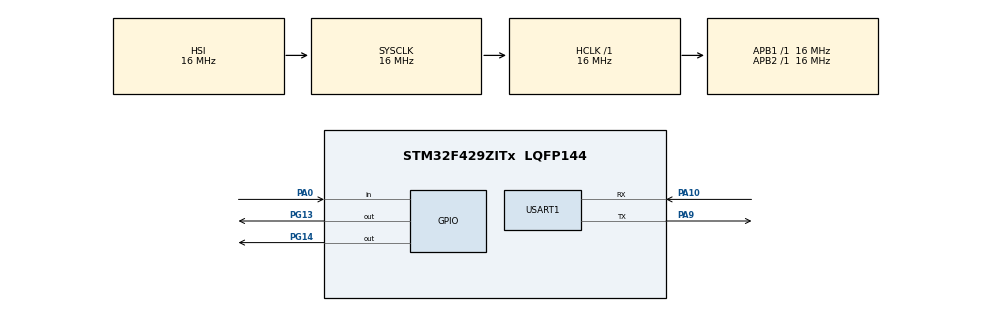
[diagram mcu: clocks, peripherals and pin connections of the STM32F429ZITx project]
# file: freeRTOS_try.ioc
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FREERTOS.BinarySemaphores01=myBinarySem01,Dynamic,NULL
FREERTOS.Tasks01=defaultTask,0,128,Thread1,Default,NULL,Dynamic,NULL,NULL;myTask02,-2,128,Thread2,Default,NULL,Dynamic,NULL,NULL
Mcu.Family=STM32F4
Mcu.Name=STM32F429ZITx
Mcu.Package=LQFP144
NVIC.PriorityGroup=NVIC_PRIORITYGROUP_4
NVIC.TIM3_IRQn=true\:0\:0\:false\:false\:true\:false\:false\:true
NVIC.TimeBase=TIM3_IRQn
NVIC.TimeBaseIP=TIM3
PA0/WKUP.Signal=GPIO_Input
PA10.Mode=Asynchronous
PA10.Signal=USART1_RX
PA13.Mode=Serial_Wire
PA13.Signal=SYS_JTMS-SWDIO
PA14.Mode=Serial_Wire
PA14.Signal=SYS_JTCK-SWCLK
PA9.Mode=Asynchronous
PA9.Signal=USART1_TX
PG13.Signal=GPIO_Output
PG14.Signal=GPIO_Output
ProjectManager.HeapSize=0x200
ProjectManager.StackSize=0x400
ProjectManager.TargetToolchain=MDK-ARM V5
RCC.AHBFreq_Value=16000000
RCC.APB1Freq_Value=16000000
RCC.APB2Freq_Value=16000000
RCC.CortexFreq_Value=16000000
RCC.HSE_VALUE=25000000
RCC.HSI_VALUE=16000000
RCC.LSE_VALUE=32768
RCC.SYSCLKFreq_VALUE=16000000
RCC.VCOOutputFreq_Value=192000000
USART1.VirtualMode=VM_ASYNC
VP_FREERTOS_VS_CMSIS_V1.Mode=CMSIS_V1
VP_SYS_VS_tim3.Mode=TIM3
board=custom

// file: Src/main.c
/* USER CODE BEGIN Header */
/**
  ******************************************************************************
  * @file           : main.c
  * @brief          : Main program body
  ******************************************************************************
  * @attention
  *
  * <h2><center>&copy; Copyright (c) 2020 STMicroelectronics.
  * All rights reserved.</center></h2>
  *
  * This software component is licensed by ST under Ultimate Liberty license
  * SLA0044, the "License"; You may not use this file except in compliance with
  * the License. You may obtain a copy of the License at:
  *                             www.st.com/SLA0044
  *
  ******************************************************************************
  */
/* USER CODE END Header */

#include "main.h"
#include "cmsis_os.h"

UART_HandleTypeDef huart1;

osThreadId defaultTaskHandle;
osThreadId myTask02Handle;
osSemaphoreId myBinarySem01Handle;

void SystemClock_Config(void);
static void MX_GPIO_Init(void);
static void MX_USART1_UART_Init(void);
void Thread1(void const * argument);
void Thread2(void const * argument);

int main(void)
{

  /* MCU Configuration--------------------------------------------------------*/

  /* Reset of all peripherals, Initializes the Flash interface and the Systick. */
  HAL_Init();

  /* Configure the system clock */
  SystemClock_Config();

  /* Initialize all configured peripherals */
  MX_GPIO_Init();
  MX_USART1_UART_Init();

  /* Create the semaphores(s) */
  /* definition and creation of myBinarySem01 */
  osSemaphoreDef(myBinarySem01);
  myBinarySem01Handle = osSemaphoreCreate(osSemaphore(myBinarySem01), 1);

  /* Create the thread(s) */
  /* definition and creation of defaultTask */
  osThreadDef(defaultTask, Thread1, osPriorityNormal, 0, 128);
  defaultTaskHandle = osThreadCreate(osThread(defaultTask), NULL);

  /* definition and creation of myTask02 */
  osThreadDef(myTask02, Thread2, osPriorityLow, 0, 128);
  myTask02Handle = osThreadCreate(osThread(myTask02), NULL);

  /* Start scheduler */
  osKernelStart();

  /* We should never get here as control is now taken by the scheduler */

  /* Infinite loop */
  while (1)
  {

  }
}

void SystemClock_Config(void)
{
  RCC_OscInitTypeDef RCC_OscInitStruct = {0};
  RCC_ClkInitTypeDef RCC_ClkInitStruct = {0};

  /** Configure the main internal regulator output voltage
  */
  __HAL_RCC_PWR_CLK_ENABLE();
  __HAL_PWR_VOLTAGESCALING_CONFIG(PWR_REGULATOR_VOLTAGE_SCALE3);
  /** Initializes the CPU, AHB and APB busses clocks
  */
  RCC_OscInitStruct.OscillatorType = RCC_OSCILLATORTYPE_HSI;
  RCC_OscInitStruct.HSIState = RCC_HSI_ON;
  RCC_OscInitStruct.HSICalibrationValue = RCC_HSICALIBRATION_DEFAULT;
  RCC_OscInitStruct.PLL.PLLState = RCC_PLL_NONE;
  if (HAL_RCC_OscConfig(&RCC_OscInitStruct) != HAL_OK)
  {
    Error_Handler();
  }
  /** Initializes the CPU, AHB and APB busses clocks
  */
  RCC_ClkInitStruct.ClockType = RCC_CLOCKTYPE_HCLK|RCC_CLOCKTYPE_SYSCLK
                              |RCC_CLOCKTYPE_PCLK1|RCC_CLOCKTYPE_PCLK2;
  RCC_ClkInitStruct.SYSCLKSource = RCC_SYSCLKSOURCE_HSI;
  RCC_ClkInitStruct.AHBCLKDivider = RCC_SYSCLK_DIV1;
  RCC_ClkInitStruct.APB1CLKDivider = RCC_HCLK_DIV1;
  RCC_ClkInitStruct.APB2CLKDivider = RCC_HCLK_DIV1;

  if (HAL_RCC_ClockConfig(&RCC_ClkInitStruct, FLASH_LATENCY_0) != HAL_OK)
  {
    Error_Handler();
  }
}

static void MX_USART1_UART_Init(void)
{

  huart1.Instance = USART1;
  huart1.Init.BaudRate = 115200;
  huart1.Init.WordLength = UART_WORDLENGTH_8B;
  huart1.Init.StopBits = UART_STOPBITS_1;
  huart1.Init.Parity = UART_PARITY_NONE;
  huart1.Init.Mode = UART_MODE_TX_RX;
  huart1.Init.HwFlowCtl = UART_HWCONTROL_NONE;
  huart1.Init.OverSampling = UART_OVERSAMPLING_16;
  if (HAL_UART_Init(&huart1) != HAL_OK)
  {
    Error_Handler();
  }

}

static void MX_GPIO_Init(void)
{
  GPIO_InitTypeDef GPIO_InitStruct = {0};

  /* GPIO Ports Clock Enable */
  __HAL_RCC_GPIOA_CLK_ENABLE();
  __HAL_RCC_GPIOG_CLK_ENABLE();

  /*Configure GPIO pin Output Level */
  HAL_GPIO_WritePin(GPIOG, GPIO_PIN_13|GPIO_PIN_14, GPIO_PIN_RESET);

  /*Configure GPIO pin : PA0 */
  GPIO_InitStruct.Pin = GPIO_PIN_0;
  GPIO_InitStruct.Mode = GPIO_MODE_INPUT;
  GPIO_InitStruct.Pull = GPIO_NOPULL;
  HAL_GPIO_Init(GPIOA, &GPIO_InitStruct);

  /*Configure GPIO pins : PG13 PG14 */
  GPIO_InitStruct.Pin = GPIO_PIN_13|GPIO_PIN_14;
  GPIO_InitStruct.Mode = GPIO_MODE_OUTPUT_PP;
  GPIO_InitStruct.Pull = GPIO_NOPULL;
  GPIO_InitStruct.Speed = GPIO_SPEED_FREQ_LOW;
  HAL_GPIO_Init(GPIOG, &GPIO_InitStruct);

}

void Thread1(void const * argument)
{

  /* USER CODE BEGIN 5 */
	uint8_t dataTX[25] = "hello from thread 1  \r\n";
  /* Infinite loop */
  for(;;)
  {

		xSemaphoreTake(&myBinarySem01Handle, portMAX_DELAY);
		HAL_GPIO_TogglePin(GPIOG, GPIO_PIN_13);
		HAL_UART_Transmit(&huart1,dataTX, 25,5 );
		xSemaphoreGive(&myBinarySem01Handle);
		osDelay(500);

  }
  /* USER CODE END 5 */
}

void Thread2(void const * argument)
{
  /* USER CODE BEGIN Thread2 */
		uint8_t dataTX[25] = "hello from thread 2  \r\n";
  /* Infinite loop */
  for(;;)
  {

		if(HAL_GPIO_ReadPin(GPIOA, GPIO_PIN_0) == GPIO_PIN_SET)
		{
					xSemaphoreTake(&myBinarySem01Handle, portMAX_DELAY);
					HAL_UART_Transmit(&huart1,dataTX, 25,5 );
			    xSemaphoreGive(&myBinarySem01Handle);
		}
    osDelay(500);
  }
  /* USER CODE END Thread2 */
}

void HAL_TIM_PeriodElapsedCallback(TIM_HandleTypeDef *htim)
{
  if (htim->Instance == TIM3) {
    HAL_IncTick();
  }
}

void Error_Handler(void)
{
}

/************************ (C) COPYRIGHT STMicroelectronics *****END OF FILE****/
